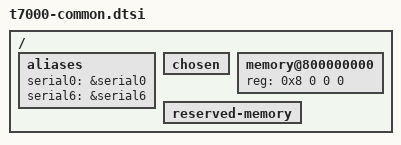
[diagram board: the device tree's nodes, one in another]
// SPDX-License-Identifier: GPL-2.0+ OR MIT
/*
 * Apple TV HD, iPhone 6, iPhone 6 Plus, iPad mini 4, iPod touch 6
 *
 * This file contains parts common to all Apple A8 devices.
 *
 * target-type: J42d, J96, J97, N56, N61, N102
 *
 * Copyright (c) 2024, Nick Chan <towinchenmi@gmail.com>
 */

/ {
	aliases {
		serial0 = &serial0;
		serial6 = &serial6;
	};

	chosen {
		#address-cells = <2>;
		#size-cells = <2>;
		ranges;
	};

	memory@800000000 {
		device_type = "memory";
		reg = <0x8 0 0 0>; /* To be filled by loader */
	};

	reserved-memory {
		#address-cells = <2>;
		#size-cells = <2>;
		ranges;

		/* To be filled by loader */
	};
};
